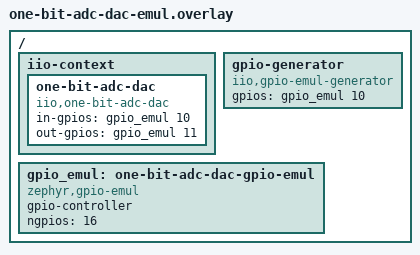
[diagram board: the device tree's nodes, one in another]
/*
 * Copyright (c) 2026 Analog Devices, Inc.
 *
 * SPDX-License-Identifier: MIT
 */

#include <zephyr/dt-bindings/gpio/gpio.h>

/ {
	iio-context {
		one-bit-adc-dac {
			compatible = "iio,one-bit-adc-dac";
			in-gpios = <&gpio_emul 10 GPIO_ACTIVE_HIGH>;
			out-gpios = <&gpio_emul 11 GPIO_ACTIVE_HIGH>;
		};
	};

	gpio-generator {
		compatible = "iio,gpio-emul-generator";
		gpios = <&gpio_emul 10 GPIO_ACTIVE_HIGH>;
	};

	gpio_emul: one-bit-adc-dac-gpio-emul {
		compatible = "zephyr,gpio-emul";
		gpio-controller;
		#gpio-cells = <2>;
		ngpios = <16>;
	};
};
